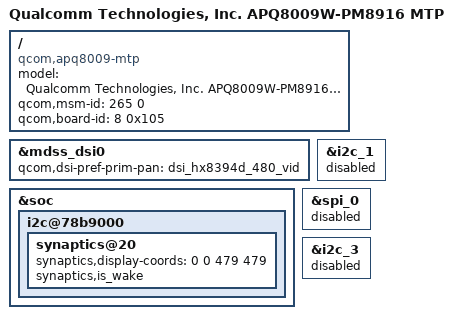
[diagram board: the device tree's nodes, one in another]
/*
 * Copyright (c) 2015, The Linux Foundation. All rights reserved.
 *
 * This program is free software; you can redistribute it and/or modify
 * it under the terms of the GNU General Public License version 2 and
 * only version 2 as published by the Free Software Foundation.
 *
 * This program is distributed in the hope that it will be useful,
 * but WITHOUT ANY WARRANTY; without even the implied warranty of
 * MERCHANTABILITY or FITNESS FOR A PARTICULAR PURPOSE.  See the
 * GNU General Public License for more details.
 */

/dts-v1/;

#include "msm8909-mtp.dtsi"
#include "msm8909-pm8916.dtsi"
#include "msm8909-pm8916-mtp.dtsi"

/ {
	model = "Qualcomm Technologies, Inc. APQ8009W-PM8916 MTP";
	compatible = "qcom,apq8009-mtp", "qcom,apq8009", "qcom,mtp";
	qcom,msm-id = <265 0>;
	qcom,board-id= <8 0x105>;
};

&mdss_dsi0 {
	qcom,dsi-pref-prim-pan = <&dsi_hx8394d_480_vid>;
};

&soc {
	i2c@78b9000 { /* BLSP1 QUP5 */
		synaptics@20 {
			synaptics,display-coords = <0 0 479 479>;
			/delete-property/ synaptics,power-down;
			/delete-property/ synaptics,disable-gpios;
			synaptics,is_wake;
		};
	};
};

&i2c_1 {
	status = "disabled";
};

&spi_0 {
	status = "disabled";
};

&i2c_3 {
	status = "disabled";
};
